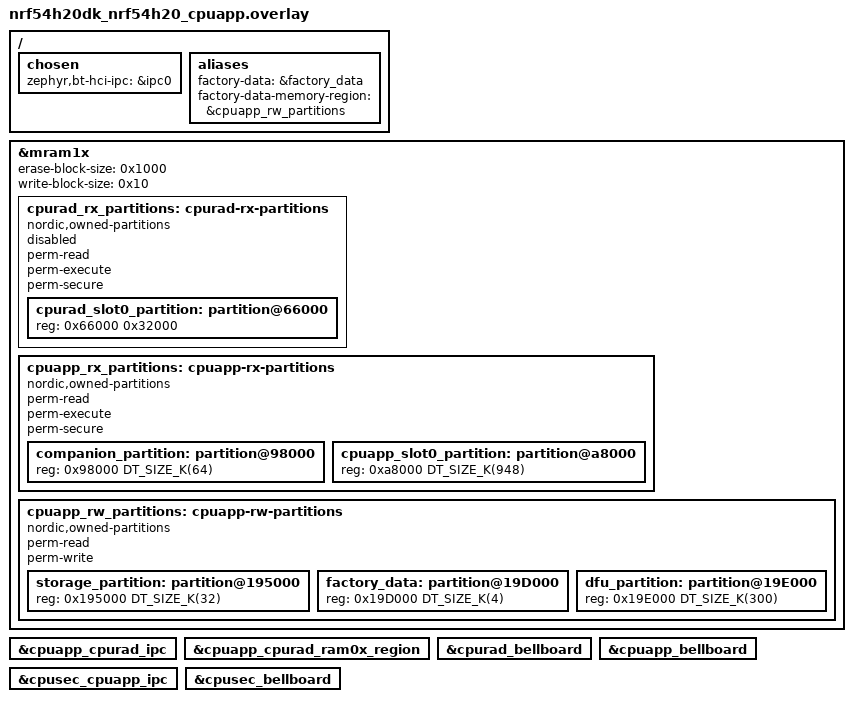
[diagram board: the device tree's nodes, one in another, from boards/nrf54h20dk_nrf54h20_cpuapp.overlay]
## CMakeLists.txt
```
#
# Copyright (c) 2021 Nordic Semiconductor ASA
#
# SPDX-License-Identifier: LicenseRef-Nordic-5-Clause
#

cmake_minimum_required(VERSION 3.20.0)

find_package(Zephyr REQUIRED HINTS $ENV{ZEPHYR_BASE})
project(matter-lock)

# Enable GNU STD support.
include(${ZEPHYR_CONNECTEDHOMEIP_MODULE_DIR}/config/nrfconnect/app/enable-gnu-std.cmake)

# NORDIC SDK APP START

# Include all source files that are located in the Matter common directory.
include(${ZEPHYR_NRF_MODULE_DIR}/samples/matter/common/cmake/source_common.cmake)

# Include Data Model utils
include(${ZEPHYR_NRF_MODULE_DIR}/samples/matter/common/cmake/data_model.cmake)

include(${ZEPHYR_NRF_MODULE_DIR}/samples/matter/common/cmake/zap_helpers.cmake)
ncs_get_zap_parent_dir(ZAP_PARENT_DIR)

target_include_directories(app PRIVATE
  src
  ${ZAP_PARENT_DIR}
)

target_sources(app PRIVATE
  src/app_task.cpp
  src/bolt_lock_manager.cpp
  src/main.cpp
  src/zcl_callbacks.cpp
  src/access/access_data_types.cpp
  src/access/access_manager_credentials.cpp
  src/access/access_manager_users.cpp
  src/access/access_manager.cpp
)

target_sources_ifdef(CONFIG_LOCK_ACCESS_STORAGE_PERSISTENT_STORAGE app PRIVATE
  src/access/access_storage.cpp
)

target_sources_ifdef(CONFIG_LOCK_ACCESS_STORAGE_PROTECTED_STORAGE app PRIVATE
  src/access/access_storage_psa_ps.cpp
)

target_sources_ifdef(CONFIG_LOCK_SCHEDULES app PRIVATE
  src/access/access_manager_schedules.cpp
)

target_sources_ifdef(CONFIG_LOCK_PRINT_STORAGE_STATUS app PRIVATE
  src/access/access_storage_print.cpp
)

target_sources_ifdef(CONFIG_THREAD_WIFI_SWITCHING app PRIVATE
  src/thread_wifi_switch.cpp
)

# Do not treat warnings as errors while the variable may be uninitialized for this sample data model.
# In the door-lock-server implementation, there is a warning that the C++ "optional"
# variable may be uninitialized, but actually, it is wrongly interpreted by the Zephyr toolchain.
target_compile_options(matter-data-model PRIVATE -Wno-error=maybe-uninitialized)

ncs_configure_data_model()

# NORDIC SDK APP END
```

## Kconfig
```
#
# Copyright (c) 2021 Nordic Semiconductor
#
# SPDX-License-Identifier: LicenseRef-Nordic-5-Clause
#

mainmenu "Matter Lock sample application"

config LOCK_MAX_NUM_USERS
	int "Maximum number of users supported by the lock"
	default 10

config LOCK_MAX_NUM_CREDENTIALS_PER_USER
	int "Maximum total number of credentials per one user supported by the lock"
	default 4

config LOCK_MAX_NUM_CREDENTIALS_PER_TYPE
	int "Maximum number of credentials of given type supported by the lock"
	default 15

config LOCK_MAX_CREDENTIAL_LENGTH
	int "Maximum length of the single credential supported by the lock"
	default 10

config LOCK_PASS_CREDENTIALS_TO_SET_LOCK_STATE
	bool "Pass used credentials when setting the lock state"
	help
	  This option should stay disabled until TC-DRLK-2.3 is fixed.
	  Related issue: https://github.com/project-chip/connectedhomeip/issues/38222

config LOCK_SCHEDULES
	bool "Support for WeekDay, YearDay and Holiday schedules in lock"
	help
	  This option adds support for an optional Timed Schedule Access Lock feature.
	  You can use Week Day, Year Day and Holiday schedules to restrict access for a
	  specific user for a defined time window. For example, use it to
	  give the user access only for three days in week.

if LOCK_SCHEDULES

config LOCK_MAX_WEEKDAY_SCHEDULES_PER_USER
	int "Maximum number of WeekDay schedules per one user supported by the lock"
	default 5

config LOCK_MAX_YEARDAY_SCHEDULES_PER_USER
	int "Maximum number of YearDay schedules per one user supported by the lock"
	default 5

config LOCK_MAX_HOLIDAY_SCHEDULES
	int "Maximum number of Holiday schedules supported by the lock"
	default 5

endif

config LOCK_ENABLE_DEBUG
	bool "Debug features to print users and credentials"
	depends on SHELL
	help
	  Debug features allows to checking and printing current users, their state, and
	  associated credentials. Use these with shell commands combinations to read saved credentials
	  or users, and manage them (add, clear, read).

if LOCK_ENABLE_DEBUG

config LOCK_PRINT_STORAGE_STATUS
	bool "Print storage status after each store call"
	# This feature assumes that items are eventually stored in Zephyr settings subsystem
	depends on LOCK_ACCESS_STORAGE_PERSISTENT_STORAGE || TRUSTED_STORAGE_STORAGE_BACKEND_SETTINGS
	help
	  Debug feature to print the debug-level log that contains information of the entry being stored
	  to persistent storage and how many bytes are left to store the new entry. It can be used to verify
	  whether credential, schedule or user entries are written properly to persistent storage.
	  This option should be disabled in production firmware
	  version.

# This should be deterined based on the maximum possible command length that depends on the LOCK_MAX_CREDENTIAL_LENGTH
config SHELL_CMD_BUFF_SIZE
	default 300

endif

config STATE_LEDS
	bool "Use LEDs to indicate the device state"
	default y
	help
	  Use LEDs to render the current state of the device such as the progress of commissioning of
	  the device into a network or the factory reset initiation. Note that setting this option to
	  'n' does not disable the LED indicating the state of the simulated bolt.

config THREAD_WIFI_SWITCHING
	bool "Switching between Thread and Wi-Fi"
	depends on SOC_SERIES_NRF54L
	depends on NET_L2_OPENTHREAD
	depends on CHIP_WIFI
	depends on !CHIP_FACTORY_RESET_ERASE_SETTINGS
	select EXPERIMENTAL
	help
	  Build the application with both Thread and Wi-Fi support and initialize
	  either transport based on the current configuration. A user can switch
	  between Thread and Wi-Fi by pressing and holding Button 3 for more than
	  10 seconds. During the switching, the device is automatically factory
	  reset and rebooted.

if THREAD_WIFI_SWITCHING

config THREAD_WIFI_SWITCHING_SHELL
	bool "Shell command for switching between Thread and Wi-Fi"
	default y if SHELL
	help
	  Add "switch_transport" shell command that initiates switching between
	  Thread and Wi-Fi transport for Matter protocol stack.

endif # THREAD_WIFI_SWITCHING

# Sample configuration used for Thread networking
if OPENTHREAD

choice OPENTHREAD_NORDIC_LIBRARY_CONFIGURATION
	default OPENTHREAD_NORDIC_LIBRARY_MTD
endchoice

choice OPENTHREAD_DEVICE_TYPE
	default OPENTHREAD_MTD
endchoice

config CHIP_ENABLE_ICD_SUPPORT
	default y

# Reduce Thread TX output power to 0 dBm for SED device
config OPENTHREAD_DEFAULT_TX_POWER
	default 0

endif # OPENTHREAD

if SHIELD_NRF7002EB2

config CHIP_WIFI
	default y

config NRF_WIFI_LOW_POWER
	default y

endif # SHIELD_NRF7002EB2

choice LOCK_ACCESS_STORAGE_CHOICE
	prompt "Access storage implementation"
	default LOCK_ACCESS_STORAGE_PROTECTED_STORAGE

config LOCK_ACCESS_STORAGE_PERSISTENT_STORAGE
	bool "Persistent storage interface"
	select NCS_SAMPLE_MATTER_PERSISTENT_STORAGE

config LOCK_ACCESS_STORAGE_PROTECTED_STORAGE
	bool "PSA Protected Storage"
	# PSA SSF Crypto Client is not ready for PSA PS backend
	depends on !CHIP_WIFI && !PSA_SSF_CRYPTO_CLIENT
	# When building with TF-M, Protected Storage is enabled by default
	select TRUSTED_STORAGE if !BUILD_WITH_TFM
	select PSA_PROTECTED_STORAGE if !BUILD_WITH_TFM

endchoice

# Increase the storage capacity if the schedules are enabled with secure storage
# This also implies increasing of the OT and Matter stacks because some operations
# performed during commissioning seem to allocate stack buffers based on the
# maximum possible secure asset size.
if LOCK_SCHEDULES && NCS_SAMPLE_MATTER_SECURE_STORAGE_BACKEND

config NCS_SAMPLE_MATTER_SECURE_STORAGE_MAX_ENTRY_NUMBER
	default 128

config TRUSTED_STORAGE_BACKEND_AEAD_MAX_DATA_SIZE
	default 3072

config OPENTHREAD_THREAD_STACK_SIZE
	default 7168

config CHIP_TASK_STACK_SIZE
	default 10240

config MAIN_STACK_SIZE
	default 7168

endif

if LOCK_ACCESS_STORAGE_PROTECTED_STORAGE

config LOCK_ACCESS_STORAGE_PROTECTED_STORAGE_UID_OFFSET
	int "Access storage PSA Protected Storage UID range start"
	default 0

endif # LOCK_ACCESS_STORAGE_PROTECTED_STORAGE

source "$(ZEPHYR_CONNECTEDHOMEIP_MODULE_DIR)/config/nrfconnect/chip-module/Kconfig.features"
source "$(ZEPHYR_CONNECTEDHOMEIP_MODULE_DIR)/config/nrfconnect/chip-module/Kconfig.defaults"
source "$(ZEPHYR_NRF_MODULE_DIR)/samples/matter/common/src/Kconfig"
source "Kconfig.zephyr"
```

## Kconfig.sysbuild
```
#
# Copyright (c) 2023 Nordic Semiconductor ASA
#
# SPDX-License-Identifier: LicenseRef-Nordic-5-Clause
#

#### Radio core selection
config NRF_DEFAULT_IPC_RADIO
	default y

# Enable IEEE802.15.4 serialization to network core
# This config automatically pulls in the `overlay-802154.conf` in the ipc_radio image
config NETCORE_IPC_RADIO_IEEE802154
	default y if SOC_SERIES_NRF53 && !WIFI_NRF70

# Enable Bluetooth serialization to network core
# This config automatically pulls in the `overlay-bt_hci_ipc.conf` in the ipc_radio image
config NETCORE_IPC_RADIO_BT_HCI_IPC
	default y if SOC_SERIES_NRF53

#### Bootloader
choice BOOTLOADER
	default BOOTLOADER_MCUBOOT if !BOARD_NRF21540DK
endchoice

if BOOTLOADER_MCUBOOT

#### DFU multi-image support
config DFU_MULTI_IMAGE_PACKAGE_BUILD
	default y

config DFU_MULTI_IMAGE_PACKAGE_APP
	default y

config PM_EXTERNAL_FLASH_MCUBOOT_SECONDARY
	default y

#### DFU network core configuration
if SOC_SERIES_NRF53

choice MCUBOOT_MODE
	default MCUBOOT_MODE_OVERWRITE_ONLY
endchoice

choice BOOT_SIGNATURE_TYPE
	default BOOT_SIGNATURE_TYPE_RSA
endchoice

config SECURE_BOOT_NETCORE
	default y

config NETCORE_APP_UPDATE
	default y

config DFU_MULTI_IMAGE_PACKAGE_NET
	default y

endif # SOC_SERIES_NRF53

if BOARD_NRF54L15DK || BOARD_NRF54LM20DK

# Disable checking the external drivers for nRF54L15 and nRF54LM20 DKs.
config PM_OVERRIDE_EXTERNAL_DRIVER_CHECK
	default y

endif # BOARD_NRF54L15DK || BOARD_NRF54LM20DK

endif # BOOTLOADER_MCUBOOT

#### Enable generating factory data
config MATTER_FACTORY_DATA_GENERATE
	default y if !BOARD_NRF21540DK

source "share/sysbuild/Kconfig"
```

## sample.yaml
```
sample:
  description: Matter Lock example
  name: Matter Lock
common:
  tags:
    - sysbuild
    - ci_samples_matter
tests:
  sample.matter.lock.debug:
    sysbuild: true
    build_only: true
    integration_platforms:
      - nrf54l15dk/nrf54l15/cpuapp/ns
      - nrf54lm20dk/nrf54lm20b/cpuapp
      - nrf54lm20dk/nrf54lm20a/cpuapp
    platform_allow:
      - nrf52840dk/nrf52840
      - nrf5340dk/nrf5340/cpuapp
      - nrf54l15dk/nrf54l15/cpuapp
      - nrf54l15dk/nrf54l15/cpuapp/ns
      - nrf54lm20dk/nrf54lm20b/cpuapp
      - nrf54lm20dk/nrf54lm20a/cpuapp
  sample.matter.lock.nrf7002eb2.debug:
    sysbuild: true
    build_only: true
    extra_args:
      - lock_SHIELD=nrf7002eb2
      - SB_CONFIG_WIFI_NRF70=y
    integration_platforms:
      - nrf54lm20dk/nrf54lm20b/cpuapp
      - nrf54lm20dk/nrf54lm20a/cpuapp
    platform_allow:
      - nrf54lm20dk/nrf54lm20b/cpuapp
      - nrf54lm20dk/nrf54lm20a/cpuapp
  sample.matter.lock.release:
    sysbuild: true
    build_only: true
    extra_args:
      - FILE_SUFFIX=release
    integration_platforms:
      - nrf5340dk/nrf5340/cpuapp
      - nrf54lm20dk/nrf54lm20b/cpuapp
      - nrf54lm20dk/nrf54lm20a/cpuapp
    platform_allow:
      - nrf52840dk/nrf52840
      - nrf5340dk/nrf5340/cpuapp
      - nrf54l15dk/nrf54l15/cpuapp
      - nrf54lm20dk/nrf54lm20b/cpuapp
      - nrf54lm20dk/nrf54lm20a/cpuapp
  sample.matter.lock.nrf7002eb2.release:
    sysbuild: true
    build_only: true
    extra_args:
      - FILE_SUFFIX=release
      - lock_SHIELD=nrf7002eb2
      - SB_CONFIG_WIFI_NRF70=y
    integration_platforms:
      - nrf54lm20dk/nrf54lm20b/cpuapp
      - nrf54lm20dk/nrf54lm20a/cpuapp
    platform_allow:
      - nrf54lm20dk/nrf54lm20b/cpuapp
      - nrf54lm20dk/nrf54lm20a/cpuapp
  sample.matter.lock.smp_dfu:
    sysbuild: true
    build_only: true
    extra_args:
      - CONFIG_CHIP_DFU_OVER_BT_SMP=y
    integration_platforms:
      - nrf52840dk/nrf52840
      - nrf5340dk/nrf5340/cpuapp
      - nrf54lm20dk/nrf54lm20b/cpuapp
      - nrf54lm20dk/nrf54lm20a/cpuapp
    platform_allow:
      - nrf52840dk/nrf52840
      - nrf5340dk/nrf5340/cpuapp
      - nrf54l15dk/nrf54l15/cpuapp
      - nrf54lm20dk/nrf54lm20b/cpuapp
      - nrf54lm20dk/nrf54lm20a/cpuapp
  sample.matter.lock.nrf7002eb2.smp_dfu:
    sysbuild: true
    build_only: true
    extra_args:
      - CONFIG_CHIP_DFU_OVER_BT_SMP=y
      - lock_SHIELD=nrf7002eb2
      - SB_CONFIG_WIFI_NRF70=y
    integration_platforms:
      - nrf54lm20dk/nrf54lm20b/cpuapp
      - nrf54lm20dk/nrf54lm20a/cpuapp
    platform_allow:
      - nrf54lm20dk/nrf54lm20b/cpuapp
      - nrf54lm20dk/nrf54lm20a/cpuapp
  sample.matter.lock.no_dfu.no_fd:
    sysbuild: true
    build_only: true
    extra_args:
      - SB_CONFIG_MATTER_OTA=n
    integration_platforms:
      - nrf21540dk/nrf52840
    platform_allow: nrf21540dk/nrf52840
  sample.matter.lock.thread_wifi_switched.smp_dfu:
    sysbuild: true
    build_only: true
    extra_args:
      - lock_SHIELD=nrf7002eb2
      - FILE_SUFFIX=thread_wifi_switched
      - SB_CONFIG_WIFI_NRF70=y
      - CONFIG_CHIP_DFU_OVER_BT_SMP=y
    integration_platforms:
      - nrf54lm20dk/nrf54lm20b/cpuapp
      - nrf54lm20dk/nrf54lm20a/cpuapp
    platform_allow:
      - nrf54lm20dk/nrf54lm20b/cpuapp
      - nrf54lm20dk/nrf54lm20a/cpuapp
  sample.matter.lock.nus:
    sysbuild: true
    build_only: true
    extra_args:
      - CONFIG_CHIP_NUS=y
      - CONFIG_BT_APP_PASSKEY=y
      - CONFIG_CHIP_NUS_FIXED_PASSKEY=112233
    integration_platforms:
      - nrf52840dk/nrf52840
    platform_allow:
      - nrf52840dk/nrf52840
      - nrf5340dk/nrf5340/cpuapp
      - nrf54l15dk/nrf54l15/cpuapp
      - nrf54lm20dk/nrf54lm20b/cpuapp
      - nrf54lm20dk/nrf54lm20a/cpuapp
  sample.matter.lock.schedules:
    sysbuild: true
    build_only: true
    extra_args:
      - EXTRA_CONF_FILE=schedules.conf
    integration_platforms:
      - nrf5340dk/nrf5340/cpuapp
    platform_allow:
      - nrf5340dk/nrf5340/cpuapp
  sample.matter.lock.release.power_consumption:
    sysbuild: true
    build_only: true
    extra_args:
      - FILE_SUFFIX=release
      - CONFIG_NCS_SAMPLE_MATTER_LEDS=n
      - CONFIG_NCS_SAMPLE_MATTER_WATCHDOG=n
      - CONFIG_CHIP_ENABLE_PAIRING_AUTOSTART=y
    integration_platforms:
      - nrf54lm20dk/nrf54lm20b/cpuapp
      - nrf54lm20dk/nrf54lm20a/cpuapp
    platform_allow:
      - nrf52840dk/nrf52840
      - nrf5340dk/nrf5340/cpuapp
      - nrf54l15dk/nrf54l15/cpuapp
      - nrf54lm20dk/nrf54lm20b/cpuapp
      - nrf54lm20dk/nrf54lm20a/cpuapp
```

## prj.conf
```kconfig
#
# Copyright (c) 2022 Nordic Semiconductor ASA
#
# SPDX-License-Identifier: LicenseRef-Nordic-5-Clause
#

# This sample uses Kconfig.defaults to set options common for all
# samples. This file should contain only options specific for this sample
# or overrides of default values.

# Enable CHIP
CONFIG_CHIP=y
CONFIG_CHIP_PROJECT_CONFIG="src/chip_project_config.h"
CONFIG_CHIP_DEVICE_PRODUCT_NAME="Matter Door Lock"

# Configure ZAP file name
CONFIG_NCS_SAMPLE_MATTER_ZAP_FILE_PATH="${APPLICATION_CONFIG_DIR}/src/default_zap/lock.zap"

# 32774 == 0x8006 (example lock-app)
CONFIG_CHIP_DEVICE_PRODUCT_ID=32774
CONFIG_STD_CPP17=y

# Enable Matter extended announcement and increase duration to 1 hour.
CONFIG_CHIP_BLE_EXT_ADVERTISING=y
CONFIG_CHIP_BLE_ADVERTISING_DURATION=60

# Add support for LEDs and buttons on Nordic development kits
CONFIG_DK_LIBRARY=y

# Bluetooth Low Energy configuration
CONFIG_BT_DEVICE_NAME="MatterLock"

# Suspend devices when the CPU goes into sleep
CONFIG_PM_DEVICE=y

# Other settings
CONFIG_THREAD_NAME=y
CONFIG_MPU_STACK_GUARD=y
CONFIG_RESET_ON_FATAL_ERROR=n
CONFIG_CHIP_LIB_SHELL=y
CONFIG_NCS_SAMPLE_MATTER_TEST_SHELL=y

# Reduce application size
CONFIG_USE_SEGGER_RTT=n
CONFIG_MATTER_LOG_LEVEL_INF=y
CONFIG_CHIP_APP_LOG_LEVEL=3
```

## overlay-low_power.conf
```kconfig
#
# Copyright (c) 2021 Nordic Semiconductor
#
# SPDX-License-Identifier: LicenseRef-Nordic-5-Clause
#

# Enable MTD Sleepy End Device
CONFIG_CHIP_ENABLE_SLEEPY_END_DEVICE_SUPPORT=y

# SED requires less aggresive BLE connection intervals
CONFIG_BT_PERIPHERAL_PREF_MIN_INT=36
CONFIG_BT_PERIPHERAL_PREF_MAX_INT=36

# Disable UART console
CONFIG_SHELL=n
CONFIG_LOG=n
CONFIG_UART_CONSOLE=n
CONFIG_SERIAL=n

# Suspend devices when the CPU goes into sleep
CONFIG_PM_DEVICE=y

# Disable auxiliary state LEDs
CONFIG_STATE_LEDS=n
```

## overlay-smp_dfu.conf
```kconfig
#
# Copyright (c) 2022 Nordic Semiconductor
#
# SPDX-License-Identifier: LicenseRef-Nordic-5-Clause
#

# MCU Manager and SMP configuration
CONFIG_MCUMGR=y
CONFIG_MCUMGR_CMD_IMG_MGMT=y
CONFIG_MCUMGR_CMD_OS_MGMT=y
CONFIG_MCUMGR_SMP_BT=y
CONFIG_MCUMGR_SMP_BT_AUTHEN=n
CONFIG_MCUMGR_BUF_COUNT=6

# Increase BT MTU and RX buffer for big size DFU messages
CONFIG_BT_L2CAP_TX_MTU=498
CONFIG_BT_BUF_ACL_TX_SIZE=251
CONFIG_BT_BUF_ACL_RX_SIZE=502

# Increase max number of pending GATT notification callbacks
CONFIG_BT_CONN_TX_MAX=6

# Increase MCUMGR_BUF_SIZE, as it must be big enough to fit MAX MTU + overhead and for single-image DFU default is 384 B
CONFIG_MCUMGR_BUF_SIZE=1024

# Increase system workqueue size, as SMP is processed within it
CONFIG_SYSTEM_WORKQUEUE_STACK_SIZE=2800
```

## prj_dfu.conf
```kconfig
#
# Copyright (c) 2021 Nordic Semiconductor ASA
#
# SPDX-License-Identifier: LicenseRef-Nordic-5-Clause
#

# Enable CHIP
CONFIG_CHIP=y
CONFIG_CHIP_PROJECT_CONFIG="src/chip_project_config.h"
CONFIG_STD_CPP14=y

# General networking settings
CONFIG_NETWORKING=y
CONFIG_NET_IPV6_NBR_CACHE=n
CONFIG_NET_IPV6_MLD=n
CONFIG_NET_SOCKETS_POLL_MAX=5

# Enable OpenThread MTD
CONFIG_NET_L2_OPENTHREAD=y

CONFIG_OPENTHREAD_MTD=y
CONFIG_OPENTHREAD_FTD=n
CONFIG_OPENTHREAD_SLAAC=y
CONFIG_OPENTHREAD_MTD_NETDIAG=y
CONFIG_OPENTHREAD_MANUAL_START=y
CONFIG_OPENTHREAD_THREAD_STACK_SIZE=6144
CONFIG_OPENTHREAD_NUM_MESSAGE_BUFFERS=64

CONFIG_OPENTHREAD_PANID=4660
CONFIG_OPENTHREAD_CHANNEL=15
CONFIG_OPENTHREAD_NETWORK_NAME="OpenThread"
CONFIG_OPENTHREAD_XPANID="11:11:11:11:22:22:22:22"

# Enable Bluetooth Low Energy
CONFIG_BT=y
CONFIG_BT_PERIPHERAL=y
CONFIG_BT_PERIPHERAL_PREF_MIN_INT=12
CONFIG_BT_PERIPHERAL_PREF_MAX_INT=12
CONFIG_BT_GAP_AUTO_UPDATE_CONN_PARAMS=y
CONFIG_BT_GATT_DYNAMIC_DB=y
CONFIG_BT_DEVICE_APPEARANCE=0
CONFIG_BT_DEVICE_NAME_DYNAMIC=y
CONFIG_BT_DEVICE_NAME_MAX=15
CONFIG_BT_DEVICE_NAME="MatterLock"
CONFIG_BT_MAX_CONN=1
CONFIG_BT_SMP=y
CONFIG_BT_PRIVACY=y
CONFIG_BT_MAX_PAIRED=0
CONFIG_BT_BONDABLE=n
CONFIG_BT_TINYCRYPT_ECC=n
CONFIG_BT_SMP_OOB_LEGACY_PAIR_ONLY=y

# Use NFC to share commissioning information
CONFIG_CHIP_NFC_COMMISSIONING=y

# Use nrf_security
CONFIG_OPENTHREAD_NRF_SECURITY_CHOICE=y

CONFIG_CC3XX_BACKEND=y
CONFIG_OBERON_BACKEND=y

CONFIG_MBEDTLS_ENABLE_HEAP=y
CONFIG_MBEDTLS_HEAP_SIZE=15360
CONFIG_MBEDTLS_TLS_LIBRARY=y
CONFIG_NRF_SECURITY_ADVANCED=y

CONFIG_MBEDTLS_AES_C=y
CONFIG_MBEDTLS_ECP_C=y
CONFIG_MBEDTLS_ECP_DP_SECP256R1_ENABLED=y
CONFIG_MBEDTLS_CTR_DRBG_C=y
CONFIG_MBEDTLS_CIPHER_MODE_CTR=y
CONFIG_MBEDTLS_ECJPAKE_C=y
CONFIG_MBEDTLS_SHA256_C=y
CONFIG_MBEDTLS_PK_C=y
CONFIG_MBEDTLS_PK_WRITE_C=y
CONFIG_MBEDTLS_X509_CREATE_C=y
CONFIG_MBEDTLS_X509_CSR_WRITE_C=y

# Use SHA256 implementation from Oberon
CONFIG_CHOICE_OBERON_MBEDTLS_SHA256_C=y

# Disable unneeded crypto operations
CONFIG_MBEDTLS_SHA512_C=n
CONFIG_MBEDTLS_CIPHER_MODE_XTS=n
CONFIG_MBEDTLS_CHACHA20_C=n
CONFIG_MBEDTLS_POLY1305_C=n
CONFIG_MBEDTLS_CHACHAPOLY_C=n
CONFIG_MBEDTLS_GCM_C=n
CONFIG_MBEDTLS_RSA_C=n
CONFIG_OBERON_MBEDTLS_AES_C=n

# Add support for LEDs and buttons on Nordic development kits
CONFIG_DK_LIBRARY=y

# Other settings
CONFIG_LOG=y
CONFIG_LOG_MODE_MINIMAL=y
CONFIG_PRINTK_SYNC=y
CONFIG_MAIN_STACK_SIZE=8192
CONFIG_INIT_STACKS=y
CONFIG_HW_STACK_PROTECTION=y
CONFIG_THREAD_NAME=y
CONFIG_SHELL=y

# Enable bootloader and DFU related configs
CONFIG_BOOTLOADER_MCUBOOT=y

# QSPI configuration
CONFIG_NORDIC_QSPI_NOR=y
CONFIG_NORDIC_QSPI_NOR_FLASH_LAYOUT_PAGE_SIZE=4096
CONFIG_NORDIC_QSPI_NOR_STACK_WRITE_BUFFER_SIZE=16

# External flash memory configuration
CONFIG_PM_EXTERNAL_FLASH=y
CONFIG_PM_EXTERNAL_FLASH_DEV_NAME="MX25R64"
CONFIG_PM_EXTERNAL_FLASH_SIZE=0x800000
CONFIG_PM_EXTERNAL_FLASH_BASE=0

# MCU Manager and SMP configuration
CONFIG_MCUMGR=y
CONFIG_MCUMGR_CMD_IMG_MGMT=y
CONFIG_MCUMGR_CMD_OS_MGMT=y
CONFIG_MCUMGR_SMP_BT=y
CONFIG_MCUMGR_SMP_BT_AUTHEN=n
CONFIG_MCUMGR_BUF_COUNT=6

# Increase BT MTU and RX buffer for big size DFU messages
CONFIG_BT_L2CAP_TX_MTU=260
CONFIG_BT_BUF_ACL_RX_SIZE=264

# Increase system workqueue size, as SMP is processed within it
CONFIG_SYSTEM_WORKQUEUE_STACK_SIZE=2800
```

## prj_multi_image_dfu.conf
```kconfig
#
# Copyright (c) 2021 Nordic Semiconductor ASA
#
# SPDX-License-Identifier: LicenseRef-Nordic-5-Clause
#

# Enable CHIP
CONFIG_CHIP=y
CONFIG_CHIP_PROJECT_CONFIG="src/chip_project_config.h"
CONFIG_STD_CPP14=y

# General networking settings
CONFIG_NETWORKING=y
CONFIG_NET_IPV6_NBR_CACHE=n
CONFIG_NET_IPV6_MLD=n
CONFIG_NET_SOCKETS_POLL_MAX=5

# Enable OpenThread MTD
CONFIG_NET_L2_OPENTHREAD=y

CONFIG_OPENTHREAD_MTD=y
CONFIG_OPENTHREAD_FTD=n
CONFIG_OPENTHREAD_SLAAC=y
CONFIG_OPENTHREAD_MTD_NETDIAG=y
CONFIG_OPENTHREAD_MANUAL_START=y
CONFIG_OPENTHREAD_THREAD_STACK_SIZE=6144
CONFIG_OPENTHREAD_NUM_MESSAGE_BUFFERS=64

CONFIG_OPENTHREAD_PANID=4660
CONFIG_OPENTHREAD_CHANNEL=15
CONFIG_OPENTHREAD_NETWORK_NAME="OpenThread"
CONFIG_OPENTHREAD_XPANID="11:11:11:11:22:22:22:22"

# Enable Thread 1.2 features
CONFIG_OPENTHREAD_THREAD_VERSION_1_2=y
CONFIG_OPENTHREAD_DUA=y
CONFIG_OPENTHREAD_MLR=y

# Enable Bluetooth Low Energy
CONFIG_BT=y
CONFIG_BT_PERIPHERAL=y
CONFIG_BT_PERIPHERAL_PREF_MIN_INT=12
CONFIG_BT_PERIPHERAL_PREF_MAX_INT=12
CONFIG_BT_GAP_AUTO_UPDATE_CONN_PARAMS=y
CONFIG_BT_GATT_DYNAMIC_DB=y
CONFIG_BT_DEVICE_APPEARANCE=0
CONFIG_BT_DEVICE_NAME_DYNAMIC=y
CONFIG_BT_DEVICE_NAME_MAX=15
CONFIG_BT_DEVICE_NAME="MatterLock"
CONFIG_BT_MAX_CONN=1

# Use NFC to share commissioning information
CONFIG_CHIP_NFC_COMMISSIONING=y

# Use nrf_security
CONFIG_OPENTHREAD_NRF_SECURITY_CHOICE=y

CONFIG_CC3XX_BACKEND=n
CONFIG_OBERON_BACKEND=y

CONFIG_MBEDTLS_ENABLE_HEAP=y
CONFIG_MBEDTLS_HEAP_SIZE=15360
CONFIG_MBEDTLS_TLS_LIBRARY=y
CONFIG_NRF_SECURITY_ADVANCED=y

CONFIG_MBEDTLS_AES_C=y
CONFIG_MBEDTLS_ECP_C=y
CONFIG_MBEDTLS_ECP_DP_SECP256R1_ENABLED=y
CONFIG_MBEDTLS_CTR_DRBG_C=y
CONFIG_MBEDTLS_CIPHER_MODE_CTR=y
CONFIG_MBEDTLS_ECJPAKE_C=y
CONFIG_MBEDTLS_SHA256_C=y
CONFIG_MBEDTLS_PK_C=y
CONFIG_MBEDTLS_PK_WRITE_C=y
CONFIG_MBEDTLS_X509_CREATE_C=y
CONFIG_MBEDTLS_X509_CSR_WRITE_C=y

# Disable unneeded crypto operations
CONFIG_MBEDTLS_SHA384_C=n
CONFIG_MBEDTLS_SHA512_C=n
CONFIG_MBEDTLS_CIPHER_MODE_XTS=n
CONFIG_MBEDTLS_CHACHA20_C=n
CONFIG_MBEDTLS_POLY1305_C=n
CONFIG_MBEDTLS_CHACHAPOLY_C=n
CONFIG_MBEDTLS_GCM_C=n
CONFIG_MBEDTLS_RSA_C=n

# Add support for LEDs and buttons on Nordic development kits
CONFIG_DK_LIBRARY=y

# Other settings
CONFIG_LOG=y
CONFIG_LOG_MODE_MINIMAL=y
CONFIG_MATTER_LOG_LEVEL_DBG=y
CONFIG_PRINTK_SYNC=y
CONFIG_MAIN_STACK_SIZE=8192
CONFIG_INIT_STACKS=y
CONFIG_HW_STACK_PROTECTION=y
CONFIG_HWINFO=y
CONFIG_THREAD_NAME=y
CONFIG_SHELL=y
CONFIG_ASSERT=y

# Enable bootloader and DFU related configs
CONFIG_BOOTLOADER_MCUBOOT=y
CONFIG_UPDATEABLE_IMAGE_NUMBER=2

# QSPI configuration
CONFIG_NORDIC_QSPI_NOR=y
CONFIG_NORDIC_QSPI_NOR_FLASH_LAYOUT_PAGE_SIZE=4096
CONFIG_NORDIC_QSPI_NOR_STACK_WRITE_BUFFER_SIZE=16

# MCU Manager and SMP configuration
CONFIG_MCUMGR=y
CONFIG_MCUMGR_CMD_IMG_MGMT=y
CONFIG_MCUMGR_CMD_OS_MGMT=y
CONFIG_MCUMGR_SMP_BT=y
CONFIG_MCUMGR_SMP_BT_AUTHEN=n
CONFIG_MCUMGR_BUF_COUNT=6

# Increase BT MTU and RX buffer for big size DFU messages
CONFIG_BT_L2CAP_TX_MTU=498
CONFIG_BT_BUF_ACL_TX_SIZE=251
CONFIG_BT_BUF_ACL_RX_SIZE=502

# Increase max number of pending GATT notification callbacks
CONFIG_BT_CONN_TX_MAX=6

# Increase system workqueue size, as SMP is processed within it
CONFIG_SYSTEM_WORKQUEUE_STACK_SIZE=2800

# FLASH nop device is enabled to prevent bus faults when mcumgr tries to access
# simulated partition with network core image data.
CONFIG_FLASH_NOP_DEVICE=y

# Enable custom SMP request to erase settings partition.
CONFIG_MCUMGR_GRP_ZEPHYR_BASIC=y
CONFIG_MCUMGR_GRP_BASIC_CMD_STORAGE_ERASE=y
```

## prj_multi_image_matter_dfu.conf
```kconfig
#
# Copyright (c) 2022 Nordic Semiconductor ASA
#
# SPDX-License-Identifier: LicenseRef-Nordic-5-Clause
#

# Enable CHIP
CONFIG_CHIP=y
CONFIG_CHIP_PROJECT_CONFIG="src/chip_project_config.h"
CONFIG_STD_CPP14=y

# General networking settings
CONFIG_NETWORKING=y
CONFIG_NET_IPV6_NBR_CACHE=n
CONFIG_NET_IPV6_MLD=n
CONFIG_NET_SOCKETS_POLL_MAX=5

# Enable OpenThread MTD
CONFIG_NET_L2_OPENTHREAD=y

CONFIG_OPENTHREAD_NORDIC_LIBRARY_MTD=y
CONFIG_OPENTHREAD_MTD=y
CONFIG_OPENTHREAD_FTD=n

CONFIG_OPENTHREAD_PANID=4660
CONFIG_OPENTHREAD_CHANNEL=15
CONFIG_OPENTHREAD_NETWORK_NAME="OpenThread"
CONFIG_OPENTHREAD_XPANID="11:11:11:11:22:22:22:22"

# Enable Thread 1.2 features
CONFIG_OPENTHREAD_THREAD_VERSION_1_2=y

# Enable Bluetooth Low Energy
CONFIG_BT=y
CONFIG_BT_PERIPHERAL=y
CONFIG_BT_PERIPHERAL_PREF_MIN_INT=36
CONFIG_BT_PERIPHERAL_PREF_MAX_INT=36
CONFIG_BT_GAP_AUTO_UPDATE_CONN_PARAMS=y
CONFIG_BT_GATT_DYNAMIC_DB=y
CONFIG_BT_DEVICE_APPEARANCE=0
CONFIG_BT_DEVICE_NAME_DYNAMIC=y
CONFIG_BT_DEVICE_NAME_MAX=15
CONFIG_BT_DEVICE_NAME="MatterLock"
CONFIG_BT_MAX_CONN=1
CONFIG_BT_L2CAP_TX_MTU=247
CONFIG_BT_BUF_ACL_RX_SIZE=251
CONFIG_BT_BUF_ACL_TX_SIZE=251
CONFIG_BT_RX_STACK_SIZE=1120

# Use NFC to share commissioning information
CONFIG_CHIP_NFC_COMMISSIONING=y

# Use nrf_security
CONFIG_OPENTHREAD_NRF_SECURITY_CHOICE=y

CONFIG_CC3XX_BACKEND=n
CONFIG_OBERON_BACKEND=y

CONFIG_MBEDTLS_ENABLE_HEAP=y
CONFIG_MBEDTLS_HEAP_SIZE=15360
CONFIG_MBEDTLS_TLS_LIBRARY=y
CONFIG_NRF_SECURITY_ADVANCED=y

CONFIG_MBEDTLS_AES_C=y
CONFIG_MBEDTLS_ECP_C=y
CONFIG_MBEDTLS_ECP_DP_SECP256R1_ENABLED=y
CONFIG_MBEDTLS_CTR_DRBG_C=y
CONFIG_MBEDTLS_CIPHER_MODE_CTR=y
CONFIG_MBEDTLS_ECJPAKE_C=y
CONFIG_MBEDTLS_SHA256_C=y
CONFIG_MBEDTLS_PK_C=y
CONFIG_MBEDTLS_PK_WRITE_C=y
CONFIG_MBEDTLS_X509_CREATE_C=y
CONFIG_MBEDTLS_X509_CSR_WRITE_C=y

# Disable unneeded crypto operations
CONFIG_MBEDTLS_SHA384_C=n
CONFIG_MBEDTLS_SHA512_C=n
CONFIG_MBEDTLS_CIPHER_MODE_XTS=n
CONFIG_MBEDTLS_CHACHA20_C=n
CONFIG_MBEDTLS_POLY1305_C=n
CONFIG_MBEDTLS_CHACHAPOLY_C=n
CONFIG_MBEDTLS_GCM_C=n
CONFIG_MBEDTLS_RSA_C=n

# Add support for LEDs and buttons on Nordic development kits
CONFIG_DK_LIBRARY=y

# Other settings
CONFIG_LOG=y
CONFIG_LOG_MODE_MINIMAL=y
CONFIG_MATTER_LOG_LEVEL_DBG=y
CONFIG_PRINTK_SYNC=y
CONFIG_MAIN_STACK_SIZE=8192
CONFIG_INIT_STACKS=y
CONFIG_HW_STACK_PROTECTION=y
CONFIG_FPU=y
CONFIG_HWINFO=y
CONFIG_THREAD_NAME=y
CONFIG_SHELL=y
CONFIG_ASSERT=y

# Enable bootloader and DFU related configs
CONFIG_BOOTLOADER_MCUBOOT=y
CONFIG_UPDATEABLE_IMAGE_NUMBER=2

# QSPI configuration
CONFIG_NORDIC_QSPI_NOR=y
CONFIG_NORDIC_QSPI_NOR_FLASH_LAYOUT_PAGE_SIZE=4096
CONFIG_NORDIC_QSPI_NOR_STACK_WRITE_BUFFER_SIZE=16

# FLASH nop device is needed to access network core image data.
CONFIG_FLASH_NOP_DEVICE=y

# Enable Matter OTA
CONFIG_CHIP_OTA_REQUESTOR=y
CONFIG_IMG_MANAGER=y
```

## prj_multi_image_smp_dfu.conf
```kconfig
#
# Copyright (c) 2021 Nordic Semiconductor ASA
#
# SPDX-License-Identifier: LicenseRef-Nordic-5-Clause
#

# Enable CHIP
CONFIG_CHIP=y
CONFIG_CHIP_PROJECT_CONFIG="src/chip_project_config.h"
CONFIG_STD_CPP14=y

# General networking settings
CONFIG_NETWORKING=y
CONFIG_NET_IPV6_NBR_CACHE=n
CONFIG_NET_IPV6_MLD=n
CONFIG_NET_SOCKETS_POLL_MAX=5

# Enable OpenThread MTD
CONFIG_NET_L2_OPENTHREAD=y

CONFIG_OPENTHREAD_NORDIC_LIBRARY_MTD=y
CONFIG_OPENTHREAD_MTD=y
CONFIG_OPENTHREAD_FTD=n

CONFIG_OPENTHREAD_PANID=4660
CONFIG_OPENTHREAD_CHANNEL=15
CONFIG_OPENTHREAD_NETWORK_NAME="OpenThread"
CONFIG_OPENTHREAD_XPANID="11:11:11:11:22:22:22:22"

# Enable Thread 1.2 features
CONFIG_OPENTHREAD_THREAD_VERSION_1_2=y

# Enable Bluetooth Low Energy
CONFIG_BT=y
CONFIG_BT_PERIPHERAL=y
CONFIG_BT_PERIPHERAL_PREF_MIN_INT=36
CONFIG_BT_PERIPHERAL_PREF_MAX_INT=36
CONFIG_BT_GAP_AUTO_UPDATE_CONN_PARAMS=y
CONFIG_BT_GATT_DYNAMIC_DB=y
CONFIG_BT_DEVICE_APPEARANCE=0
CONFIG_BT_DEVICE_NAME_DYNAMIC=y
CONFIG_BT_DEVICE_NAME_MAX=15
CONFIG_BT_DEVICE_NAME="MatterLock"
CONFIG_BT_MAX_CONN=1
CONFIG_BT_RX_STACK_SIZE=1120

# Use NFC to share commissioning information
CONFIG_CHIP_NFC_COMMISSIONING=y

# Use nrf_security
CONFIG_OPENTHREAD_NRF_SECURITY_CHOICE=y

CONFIG_CC3XX_BACKEND=n
CONFIG_OBERON_BACKEND=y

CONFIG_MBEDTLS_ENABLE_HEAP=y
CONFIG_MBEDTLS_HEAP_SIZE=15360
CONFIG_MBEDTLS_TLS_LIBRARY=y
CONFIG_NRF_SECURITY_ADVANCED=y

CONFIG_MBEDTLS_AES_C=y
CONFIG_MBEDTLS_ECP_C=y
CONFIG_MBEDTLS_ECP_DP_SECP256R1_ENABLED=y
CONFIG_MBEDTLS_CTR_DRBG_C=y
CONFIG_MBEDTLS_CIPHER_MODE_CTR=y
CONFIG_MBEDTLS_ECJPAKE_C=y
CONFIG_MBEDTLS_SHA256_C=y
CONFIG_MBEDTLS_PK_C=y
CONFIG_MBEDTLS_PK_WRITE_C=y
CONFIG_MBEDTLS_X509_CREATE_C=y
CONFIG_MBEDTLS_X509_CSR_WRITE_C=y

# Disable unneeded crypto operations
CONFIG_MBEDTLS_SHA384_C=n
CONFIG_MBEDTLS_SHA512_C=n
CONFIG_MBEDTLS_CIPHER_MODE_XTS=n
CONFIG_MBEDTLS_CHACHA20_C=n
CONFIG_MBEDTLS_POLY1305_C=n
CONFIG_MBEDTLS_CHACHAPOLY_C=n
CONFIG_MBEDTLS_GCM_C=n
CONFIG_MBEDTLS_RSA_C=n

# Add support for LEDs and buttons on Nordic development kits
CONFIG_DK_LIBRARY=y

# Other settings
CONFIG_LOG=y
CONFIG_LOG_MODE_MINIMAL=y
CONFIG_MATTER_LOG_LEVEL_DBG=y
CONFIG_PRINTK_SYNC=y
CONFIG_MAIN_STACK_SIZE=8192
CONFIG_INIT_STACKS=y
CONFIG_HW_STACK_PROTECTION=y
CONFIG_FPU=y
CONFIG_HWINFO=y
CONFIG_THREAD_NAME=y
CONFIG_SHELL=y
CONFIG_ASSERT=y

# Enable bootloader and DFU related configs
CONFIG_BOOTLOADER_MCUBOOT=y
CONFIG_UPDATEABLE_IMAGE_NUMBER=2

# QSPI configuration
CONFIG_NORDIC_QSPI_NOR=y
CONFIG_NORDIC_QSPI_NOR_FLASH_LAYOUT_PAGE_SIZE=4096
CONFIG_NORDIC_QSPI_NOR_STACK_WRITE_BUFFER_SIZE=16

# MCU Manager and SMP configuration
CONFIG_MCUMGR=y
CONFIG_MCUMGR_CMD_IMG_MGMT=y
CONFIG_MCUMGR_CMD_OS_MGMT=y
CONFIG_MCUMGR_SMP_BT=y
CONFIG_MCUMGR_SMP_BT_AUTHEN=n
CONFIG_MCUMGR_BUF_COUNT=6

# Increase BT MTU and RX buffer for big size DFU messages
CONFIG_BT_L2CAP_TX_MTU=498
CONFIG_BT_BUF_ACL_TX_SIZE=251
CONFIG_BT_BUF_ACL_RX_SIZE=502

# Increase max number of pending GATT notification callbacks
CONFIG_BT_CONN_TX_MAX=6

# Increase system workqueue size, as SMP is processed within it
CONFIG_SYSTEM_WORKQUEUE_STACK_SIZE=2800

# FLASH nop device is enabled to prevent bus faults when mcumgr tries to access
# simulated partition with network core image data.
CONFIG_FLASH_NOP_DEVICE=y

# Enable custom SMP request to erase settings partition.
CONFIG_MCUMGR_GRP_ZEPHYR_BASIC=y
CONFIG_MCUMGR_GRP_BASIC_CMD_STORAGE_ERASE=y

# Enable Matter OTA
CONFIG_CHIP_OTA_REQUESTOR=y
```

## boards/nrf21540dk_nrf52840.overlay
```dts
/* Copyright (c) 2021 Nordic Semiconductor ASA
 *
 * SPDX-License-Identifier: LicenseRef-Nordic-5-Clause
 */

/ {
	/*
	* In some default configurations within the nRF Connect SDK,
	* e.g. on nRF52840, the chosen zephyr,entropy node is &cryptocell.
	* This devicetree overlay ensures that default is overridden wherever it
	* is set, as this application uses the RNG node for entropy exclusively.
	*/
	chosen {
		zephyr,entropy = &rng;
	};
};

/* Disable unused peripherals to reduce power consumption */
&adc {
	status = "disabled";
};
&uart1 {
	status = "disabled";
};
&gpio1 {
	status = "disabled";
};
&i2c0 {
	status = "disabled";
};
&pwm0 {
	status = "disabled";
};
&spi1 {
	status = "disabled";
};
&spi3 {
	status = "disabled";
};
&usbd {
	status = "disabled";
};
```

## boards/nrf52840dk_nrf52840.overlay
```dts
/*
 * Copyright (c) 2021 Nordic Semiconductor ASA
 *
 * SPDX-License-Identifier: LicenseRef-Nordic-5-Clause
 */

#include <samples/matter/nrf52840_partitions.dtsi>

/ {
	chosen {
		nordic,pm-ext-flash = &mx25r64;
	};
};

&mx25r64 {
	status = "okay";
};

/* Disable unused peripherals to reduce power consumption */
&adc {
	status = "disabled";
};

&uart1 {
	status = "disabled";
};

&i2c0 {
	status = "disabled";
};

&pwm0 {
	status = "disabled";
};

&spi1 {
	status = "disabled";
};

&spi3 {
	status = "disabled";
};

&usbd {
	status = "disabled";
};
```

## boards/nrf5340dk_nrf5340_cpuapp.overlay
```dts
/*
 * Copyright (c) 2021 Nordic Semiconductor ASA
 *
 * SPDX-License-Identifier: LicenseRef-Nordic-5-Clause
 */

#include <zephyr/dt-bindings/ipc_service/static_vrings.h>

/ {
	chosen {
		nordic,pm-ext-flash = &mx25r64;
	};
};

/* Set IPC thread priority to the highest value to not collide with other threads. */
&ipc0 {
	zephyr,priority = <0 PRIO_COOP>;
};

/* Disable unused peripherals to reduce power consumption */
&adc {
	status = "disabled";
};
&i2c1 {
	status = "disabled";
};
&pwm0 {
	status = "disabled";
};
&spi2 {
	status = "disabled";
};
&usbd {
	status = "disabled";
};
```

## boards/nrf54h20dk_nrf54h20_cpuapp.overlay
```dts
/*
 * Copyright (c) 2024 Nordic Semiconductor ASA
 *
 * SPDX-License-Identifier: LicenseRef-Nordic-5-Clause
 */

/ {
	chosen {
		/* prepare IPC to HCI Radio core */
		zephyr,bt-hci-ipc = &ipc0;
	};

	aliases {
		factory-data = &factory_data;
		factory-data-memory-region = &cpuapp_rw_partitions;
	};
};

/**************************************************************
Redefine MRAM memory (Partitions)
**************************************************************/
/* We need to redefine partitions to meet Matter requirements */
/delete-node/ &cpuapp_rx_partitions;
/delete-node/ &cpuapp_rw_partitions;
/delete-node/ &cpurad_rx_partitions;
/delete-node/ &cpuppr_vpr;
/delete-node/ &cpuapp_cpuppr_ipc;

&mram1x {
	erase-block-size = < 0x1000 >;
	write-block-size = < 0x10 >;

	cpurad_rx_partitions: cpurad-rx-partitions {
		compatible = "nordic,owned-partitions", "fixed-partitions";
		status = "disabled";
		perm-read;
		perm-execute;
		perm-secure;
		#address-cells = < 0x1 >;
		#size-cells = < 0x1 >;
		cpurad_slot0_partition: partition@66000 {
			reg = < 0x66000 0x32000 >;
		};
	};

	cpuapp_rx_partitions: cpuapp-rx-partitions {
		compatible = "nordic,owned-partitions", "fixed-partitions";
		status = "okay";
		perm-read;
		perm-execute;
		perm-secure;
		#address-cells = <1>;
		#size-cells = <1>;

		companion_partition: partition@98000 {
			reg = <0x98000 DT_SIZE_K(64)>;
		};

		cpuapp_slot0_partition: partition@a8000 {
			reg = <0xa8000 DT_SIZE_K(948)>;
		};
	};

	cpuapp_rw_partitions: cpuapp-rw-partitions {
		compatible = "nordic,owned-partitions", "fixed-partitions";
		status = "okay";
		perm-read;
		perm-write;
		#address-cells = < 0x1 >;
		#size-cells = < 0x1 >;

		storage_partition: partition@195000 {
			reg = < 0x195000 DT_SIZE_K(32) >;
		};

		factory_data: partition@19D000 {
			reg = < 0x19D000 DT_SIZE_K(4) >;
		};

		dfu_partition: partition@19E000 {
			reg = < 0x19E000 DT_SIZE_K(300) >;
		};

	};
};

/**************************************************************
Enable required peripherals
**************************************************************/
/* Communication between Application and Radio Cores */
ipc0: &cpuapp_cpurad_ipc {
	status = "okay";
};
&cpuapp_cpurad_ram0x_region {
	status = "okay";
};
&cpurad_bellboard {
	status = "okay";
};
&cpuapp_bellboard {
	status = "okay";
};

/* Communication between Application Core and Secure domain for SUIT */
&cpusec_cpuapp_ipc {
	status = "okay";
};
&cpusec_bellboard {
	status = "okay";
};
```

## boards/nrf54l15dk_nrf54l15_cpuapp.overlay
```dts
/*
 * Copyright (c) 2024 Nordic Semiconductor ASA
 *
 * SPDX-License-Identifier: LicenseRef-Nordic-5-Clause
 */

#include <samples/matter/nrf54l15_cpuapp_partitions.dtsi>

/ {
	aliases {
		/* Use watchdog wdt31 as the application watchdog */
		watchdog0 = &wdt31;
	};

	chosen {
		nordic,pm-ext-flash = &mx25r64;
	};
};

&mx25r64 {
	status = "okay";
};

&wdt31 {
	status = "okay";
};
```

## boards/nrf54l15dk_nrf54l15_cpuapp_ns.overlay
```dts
/*
 * Copyright (c) 2024 Nordic Semiconductor ASA
 *
 * SPDX-License-Identifier: LicenseRef-Nordic-5-Clause
 */

/ {
	aliases {
		/* Use watchdog wdt31 as the application watchdog */
		watchdog0 = &wdt31;
	};

	chosen {
		nordic,pm-ext-flash = &mx25r64;
	};
};

/* restore full RRAM and SRAM space - by default some parts are dedicated to FLRP */
&cpuapp_rram {
	reg = <0x0 DT_SIZE_K(1524)>;
};

&cpuapp_sram {
	reg = <0x20000000 DT_SIZE_K(256)>;
	ranges = <0x0 0x20000000 0x40000>;
};

&mx25r64 {
	status = "okay";
};

&wdt31 {
	status = "okay";
};

/* Change IRQ ids to handle button interrupts.
 * The default values for nRF54L15 are 219 and 269,
 * but with TF-M they are reserved for the secure domain
 * (218 and 268 are reserved for the non-secure domain).
 */
&gpiote20 {
	interrupts = <218 NRF_DEFAULT_IRQ_PRIORITY>;
};

&gpiote30 {
	interrupts = <268 NRF_DEFAULT_IRQ_PRIORITY>;
};
```

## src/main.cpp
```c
/*
 * Copyright (c) 2021 Nordic Semiconductor ASA
 *
 * SPDX-License-Identifier: LicenseRef-Nordic-5-Clause
 */

#include "app_task.h"

#include <access/access_storage.h>
#include <zephyr/logging/log.h>

LOG_MODULE_REGISTER(app, CONFIG_CHIP_APP_LOG_LEVEL);

int main()
{
	CHIP_ERROR err = AppTask::Instance().StartApp();

	LOG_ERR("Exited with code %" CHIP_ERROR_FORMAT, err.Format());
	return err == CHIP_NO_ERROR ? EXIT_SUCCESS : EXIT_FAILURE;
}

bool AppFactoryResetHandler()
{
	return AccessStorage::Instance().FactoryReset();
}
```

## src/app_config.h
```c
/*
 * Copyright (c) 2022 Nordic Semiconductor ASA
 *
 * SPDX-License-Identifier: LicenseRef-Nordic-5-Clause
 */

#pragma once

#include "board_util.h"

/* ---- Lock Example App Config ---- */

#define FUNCTION_BUTTON DK_BTN1
#define FUNCTION_BUTTON_MASK DK_BTN1_MSK

#if NUMBER_OF_BUTTONS == 2
#define BLE_ADVERTISEMENT_START_AND_LOCK_BUTTON DK_BTN2
#define BLE_ADVERTISEMENT_START_AND_LOCK_BUTTON_MASK DK_BTN2_MSK
#else
#define LOCK_BUTTON DK_BTN2
#define LOCK_BUTTON_MASK DK_BTN2_MSK
#define THREAD_WIFI_SWITCH_BUTTON DK_BTN3
#define THREAD_WIFI_SWITCH_BUTTON_MASK DK_BTN3_MSK
#define BLE_ADVERTISEMENT_START_BUTTON DK_BTN4
#define BLE_ADVERTISEMENT_START_BUTTON_MASK DK_BTN4_MSK
#endif

#define SYSTEM_STATE_LED DK_LED1
#define LOCK_STATE_LED DK_LED2
#if NUMBER_OF_LEDS == 4
#define FACTORY_RESET_SIGNAL_LED DK_LED3
#define FACTORY_RESET_SIGNAL_LED1 DK_LED4
#endif
```

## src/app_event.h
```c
/*
 * Copyright (c) 2021 Nordic Semiconductor ASA
 *
 * SPDX-License-Identifier: LicenseRef-Nordic-5-Clause
 */

#pragma once

#include <cstdint>

#include "event_types.h"

class LEDWidget;

enum class AppEventType : uint8_t {
	None = 0,
	Button,
	ButtonPushed,
	ButtonReleased,
	Timer,
	UpdateLedState,
	IdentifyStart,
	IdentifyStop,
	NUSCommand,
};

enum class FunctionEvent : uint8_t { NoneSelected = 0, SoftwareUpdate = 0, FactoryReset, AdvertisingStart };

struct AppEvent {
	union {
		struct {
			uint8_t PinNo;
			uint8_t Action;
		} ButtonEvent;
		struct {
			void *Context;
		} TimerEvent;
		struct {
			uint8_t Action;
			int32_t Actor;
		} LockEvent;
		struct {
			LEDWidget *LedWidget;
		} UpdateLedStateEvent;
	};

	AppEventType Type{ AppEventType::None };
	EventHandler Handler;
};
```

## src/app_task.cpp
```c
/*
 * Copyright (c) 2021 Nordic Semiconductor ASA
 *
 * SPDX-License-Identifier: LicenseRef-Nordic-5-Clause
 */

#include "app_task.h"
#include "bolt_lock_manager.h"
#include "clusters/identify.h"

#ifdef CONFIG_THREAD_WIFI_SWITCHING
#include "thread_wifi_switch.h"
#endif

#include "app/matter_init.h"
#include "app/task_executor.h"

#ifdef CONFIG_CHIP_NUS
#include "bt_nus/bt_nus_service.h"
#endif

#include <app-common/zap-generated/attributes/Accessors.h>
#include <app/clusters/door-lock-server/door-lock-server.h>
#include <platform/CHIPDeviceLayer.h>
#include <setup_payload/OnboardingCodesUtil.h>

#include <zephyr/logging/log.h>

LOG_MODULE_DECLARE(app, CONFIG_CHIP_APP_LOG_LEVEL);

using namespace ::chip;
using namespace ::chip::app;
using namespace ::chip::DeviceLayer;

namespace
{
constexpr EndpointId kLockEndpointId = 1;

#ifdef CONFIG_CHIP_NUS
constexpr uint16_t kAdvertisingIntervalMin = 400;
constexpr uint16_t kAdvertisingIntervalMax = 500;
constexpr uint8_t kLockNUSPriority = 2;
#endif

#ifdef CONFIG_THREAD_WIFI_SWITCHING
k_timer sSwitchTransportTimer;
constexpr uint32_t kSwitchTransportTimeout = 10000;
#endif

#define APPLICATION_BUTTON_MASK DK_BTN2_MSK
#define SWITCHING_BUTTON_MASK DK_BTN3_MSK

#ifndef CONFIG_CHIP_FACTORY_RESET_ERASE_SETTINGS
void AppFactoryResetHandler(const ChipDeviceEvent *event, intptr_t /* unused */)
{
	switch (event->Type) {
	case DeviceEventType::kFactoryReset:
		BoltLockMgr().FactoryReset();
		break;
	default:
		break;
	}
}
#endif

Nrf::Matter::IdentifyCluster sIdentifyCluster(kLockEndpointId, false, []() {
	Nrf::PostTask([] { Nrf::GetBoard().GetLED(Nrf::DeviceLeds::LED2).Set(BoltLockMgr().IsLocked()); });
});
} /* namespace */

void AppTask::ButtonEventHandler(Nrf::ButtonState state, Nrf::ButtonMask hasChanged)
{
	if ((APPLICATION_BUTTON_MASK & hasChanged) & state) {
		Nrf::PostTask([] { LockActionEventHandler(); });
	}

#ifdef CONFIG_THREAD_WIFI_SWITCHING
	if (SWITCHING_BUTTON_MASK & hasChanged) {
		SwitchButtonAction action =
			(SWITCHING_BUTTON_MASK & state) ? SwitchButtonAction::Pressed : SwitchButtonAction::Released;
		Nrf::PostTask([action] { SwitchTransportTriggerHandler(action); });
	}
#endif
}

void AppTask::LockActionEventHandler()
{
	if (BoltLockMgr().IsLocked()) {
		BoltLockMgr().Unlock(BoltLockManager::OperationSource::kButton);
	} else {
		BoltLockMgr().Lock(BoltLockManager::OperationSource::kButton);
	}
}

#ifdef CONFIG_THREAD_WIFI_SWITCHING
void AppTask::SwitchTransportEventHandler()
{
	LOG_INF("Switching to %s", ThreadWifiSwitch::IsThreadActive() ? "Wi-Fi" : "Thread");

	ThreadWifiSwitch::SwitchTransport();
}

void AppTask::SwitchTransportTimerTimeoutCallback(k_timer *timer)
{
	Nrf::PostTask([] { SwitchTransportEventHandler(); });
}

void AppTask::SwitchTransportTriggerHandler(const SwitchButtonAction &action)
{
	if (action == SwitchButtonAction::Pressed) {
		LOG_INF("Keep button pressed for %u ms to switch to %s", kSwitchTransportTimeout,
			ThreadWifiSwitch::IsThreadActive() ? "Wi-Fi" : "Thread");
		k_timer_start(&sSwitchTransportTimer, K_MSEC(kSwitchTransportTimeout), K_NO_WAIT);
	} else {
		LOG_INF("Switching to %s cancelled", ThreadWifiSwitch::IsThreadActive() ? "Wi-Fi" : "Thread");
		k_timer_stop(&sSwitchTransportTimer);
	}
}
#endif

void AppTask::LockStateChanged(const BoltLockManager::StateData &stateData)
{
	switch (stateData.mState) {
	case BoltLockManager::State::kLockingInitiated:
		LOG_INF("Lock action initiated");
		Nrf::GetBoard().GetLED(Nrf::DeviceLeds::LED2).Blink(50, 50);
#ifdef CONFIG_CHIP_NUS
		Nrf::GetNUSService().SendData("locking", sizeof("locking"));
#endif
		break;
	case BoltLockManager::State::kLockingCompleted:
		LOG_INF("Lock action completed");
		Nrf::GetBoard().GetLED(Nrf::DeviceLeds::LED2).Set(true);
#ifdef CONFIG_CHIP_NUS
		Nrf::GetNUSService().SendData("locked", sizeof("locked"));
#endif
		break;
	case BoltLockManager::State::kUnlockingInitiated:
		LOG_INF("Unlock action initiated");
		Nrf::GetBoard().GetLED(Nrf::DeviceLeds::LED2).Blink(50, 50);
#ifdef CONFIG_CHIP_NUS
		Nrf::GetNUSService().SendData("unlocking", sizeof("unlocking"));
#endif
		break;
	case BoltLockManager::State::kUnlockingCompleted:
		LOG_INF("Unlock action completed");
#ifdef CONFIG_CHIP_NUS
		Nrf::GetNUSService().SendData("unlocked", sizeof("unlocked"));
#endif
		Nrf::GetBoard().GetLED(Nrf::DeviceLeds::LED2).Set(false);
		break;
	}

	/* Handle changing attribute state in the application */
	Instance().UpdateClusterState(stateData);
}

void AppTask::UpdateClusterState(const BoltLockManager::StateData &stateData)
{
	BoltLockManager::StateData *stateDataCopy = Platform::New<BoltLockManager::StateData>(stateData);

	if (stateDataCopy == nullptr) {
		LOG_ERR("Failed to allocate memory for BoltLockManager::StateData");
		return;
	}

	CHIP_ERROR err = SystemLayer().ScheduleLambda([stateDataCopy]() {
		UpdateClusterStateHandler(*stateDataCopy);
		Platform::Delete(stateDataCopy);
	});

	if (err != CHIP_NO_ERROR) {
		LOG_ERR("Failed to schedule lambda: %" CHIP_ERROR_FORMAT, err.Format());
		Platform::Delete(stateDataCopy);
	}
}

void AppTask::UpdateClusterStateHandler(const BoltLockManager::StateData &stateData)
{
	using namespace chip::app::Clusters::DoorLock::Attributes;

	DlLockState newLockState;

	switch (stateData.mState) {
	case BoltLockManager::State::kLockingCompleted:
		newLockState = DlLockState::kLocked;
		break;
	case BoltLockManager::State::kUnlockingCompleted:
		newLockState = DlLockState::kUnlocked;
		break;
	default:
		newLockState = DlLockState::kNotFullyLocked;
		break;
	}

	Nullable<DlLockState> currentLockState;
	LockState::Get(kLockEndpointId, currentLockState);

	if (currentLockState.IsNull()) {
		/* Initialize lock state with start value, but not invoke lock/unlock. */
		LockState::Set(kLockEndpointId, newLockState);
	} else {
		LOG_INF("Updating LockState attribute");

		Nullable<uint16_t> userId;
		Nullable<List<const LockOpCredentials>> credentials;
#ifdef CONFIG_LOCK_PASS_CREDENTIALS_TO_SET_LOCK_STATE
		List<const LockOpCredentials> credentialList;
#endif

		if (!stateData.mValidatePINResult.IsNull()) {
			userId = { stateData.mValidatePINResult.Value().mUserId };

#ifdef CONFIG_LOCK_PASS_CREDENTIALS_TO_SET_LOCK_STATE
			/* `DoorLockServer::SetLockState` exptects list of `LockOpCredentials`,
			   however in case of PIN validation it makes no sense to have more than one
			   credential corresponding to validation result. For simplicity we wrap single
			   credential in list here. */
			credentialList = { &stateData.mValidatePINResult.Value().mCredential, 1 };
			credentials = { credentialList };
#endif
		}

		if (!DoorLockServer::Instance().SetLockState(kLockEndpointId, newLockState, stateData.mSource, userId,
							     credentials, stateData.mFabricIdx, stateData.mNodeId)) {
			LOG_ERR("Failed to update LockState attribute");
		}
	}
}

#ifdef CONFIG_CHIP_NUS
void AppTask::NUSLockCallback(void *context)
{
	LOG_DBG("Received LOCK command from NUS");
	if (BoltLockMgr().GetState().mState == BoltLockManager::State::kLockingCompleted ||
	    BoltLockMgr().GetState().mState == BoltLockManager::State::kLockingInitiated) {
		LOG_INF("Device is already locked");
	} else {
		Nrf::PostTask([] { LockActionEventHandler(); });
	}
}

void AppTask::NUSUnlockCallback(void *context)
{
	LOG_DBG("Received UNLOCK command from NUS");
	if (BoltLockMgr().GetState().mState == BoltLockManager::State::kUnlockingCompleted ||
	    BoltLockMgr().GetState().mState == BoltLockManager::State::kUnlockingInitiated) {
		LOG_INF("Device is already unlocked");
	} else {
		Nrf::PostTask([] { LockActionEventHandler(); });
	}
}
#endif

#ifdef CONFIG_NCS_SAMPLE_MATTER_TEST_EVENT_TRIGGERS
CHIP_ERROR AppTask::DoorLockJammedEventCallback(Nrf::Matter::TestEventTrigger::TriggerValue)
{
	VerifyOrReturnError(DoorLockServer::Instance().SendLockAlarmEvent(kLockEndpointId, AlarmCodeEnum::kLockJammed),
			    CHIP_ERROR_INTERNAL);
	LOG_ERR("Event Trigger: Doorlock jammed.");
	return CHIP_NO_ERROR;
}
#endif

CHIP_ERROR AppTask::Init()
{
	/* Initialize Matter stack */
#ifdef CONFIG_THREAD_WIFI_SWITCHING
	/* In the Thread/Wi-Fi switchable mode, it is the ThreadWifiSwitch module that owns the NetworkCommissioning
	   instances, so offload the initialization module from controlling that by explicitly setting the
	   mNetworkingInstance parameter to nullptr. Otherwise, the initialization module instantiates the
	   NetworkCommissioning object and handles it by default internally. */
	ReturnErrorOnFailure(Nrf::Matter::PrepareServer(Nrf::Matter::InitData{ .mNetworkingInstance = nullptr }));
#else
	ReturnErrorOnFailure(Nrf::Matter::PrepareServer());
#endif

	if (!Nrf::GetBoard().Init(ButtonEventHandler)) {
		LOG_ERR("User interface initialization failed.");
		return CHIP_ERROR_INCORRECT_STATE;
	}

	/* Register Matter event handler that controls the connectivity status LED based on the captured Matter network
	 * state. */
	ReturnErrorOnFailure(Nrf::Matter::RegisterEventHandler(Nrf::Board::DefaultMatterEventHandler, 0));

#ifndef CONFIG_CHIP_FACTORY_RESET_ERASE_SETTINGS
	/* Register factory reset event handler.
	 * With this configuration we have to manually clean up the storage,
	 * as whole settings partition won't be erased.
	 * */
	ReturnErrorOnFailure(Nrf::Matter::RegisterEventHandler(AppFactoryResetHandler, 0));
#endif

#ifdef CONFIG_THREAD_WIFI_SWITCHING
	CHIP_ERROR err = ThreadWifiSwitch::StartCurrentTransport();
	if (err != CHIP_NO_ERROR) {
		LOG_ERR("ThreadWifiSwitch::StartCurrentTransport() failed: %" CHIP_ERROR_FORMAT, err.Format());
		return err;
	}

	k_timer_init(&sSwitchTransportTimer, &AppTask::SwitchTransportTimerTimeoutCallback, nullptr);
#endif

#ifdef CONFIG_CHIP_NUS
	/* Initialize Nordic UART Service for Lock purposes */
	if (!Nrf::GetNUSService().Init(kLockNUSPriority, kAdvertisingIntervalMin, kAdvertisingIntervalMax)) {
		ChipLogError(Zcl, "Cannot initialize NUS service");
	}
	Nrf::GetNUSService().RegisterCommand("Lock", sizeof("Lock"), NUSLockCallback, nullptr);
	Nrf::GetNUSService().RegisterCommand("Unlock", sizeof("Unlock"), NUSUnlockCallback, nullptr);
	if (!Nrf::GetNUSService().StartServer()) {
		LOG_ERR("GetNUSService().StartServer() failed");
	}
#endif

	/* Initialize lock manager */
	BoltLockMgr().Init(LockStateChanged);

	/* Register Door Lock test event trigger */
#ifdef CONFIG_NCS_SAMPLE_MATTER_TEST_EVENT_TRIGGERS
	ReturnErrorOnFailure(Nrf::Matter::TestEventTrigger::Instance().RegisterTestEventTrigger(
		kDoorLockJammedEventTriggerId,
		Nrf::Matter::TestEventTrigger::EventTrigger{ 0, DoorLockJammedEventCallback }));
#endif

	ReturnErrorOnFailure(sIdentifyCluster.Init());

	return Nrf::Matter::StartServer();
}

CHIP_ERROR AppTask::StartApp()
{
	ReturnErrorOnFailure(Init());

	while (true) {
		Nrf::DispatchNextTask();
	}

	return CHIP_NO_ERROR;
}
```

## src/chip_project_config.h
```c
/*
 * Copyright (c) 2021 Nordic Semiconductor ASA
 *
 * SPDX-License-Identifier: LicenseRef-Nordic-5-Clause
 */

/**
 *    @file
 *          Example project configuration file for CHIP.
 *
 *          This is a place to put application or project-specific overrides
 *          to the default configuration values for general CHIP features.
 *
 */

#pragma once

#ifdef CONFIG_THREAD_WIFI_SWITCHING
/*
 * Reduce the code size by disabling ZCL progress level logs.
 * Door Lock cluster logs are extremely verbose and significantly increase the code size.
 */
#define CHIP_CONFIG_LOG_MODULE_Zcl_PROGRESS 0

/* Do not automatically register Thread Network Commissioning instance. */
#define _NO_NETWORK_COMMISSIONING_DRIVER_
#endif
```
